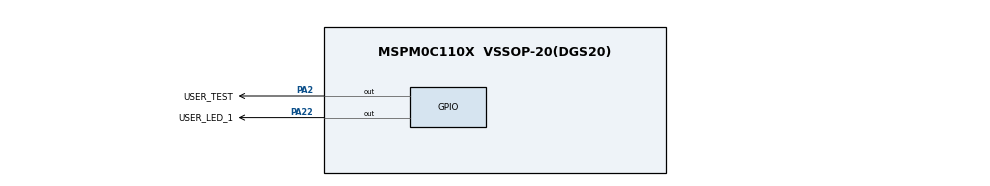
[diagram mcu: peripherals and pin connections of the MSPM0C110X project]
/**
 * @cliArgs --device "MSPM0C110X" --part "Default" --package "VSSOP-20(DGS20)" --product "mspm0_sdk@2.04.00.06"
 * @versions {"tool":"1.22.0+3893"}
 */

/**
 * Import the modules used in this configuration.
 */
const GPIO          = scripting.addModule("/ti/driverlib/GPIO", {}, false);
const GPIO1         = GPIO.addInstance();
const SYSCTL        = scripting.addModule("/ti/driverlib/SYSCTL");
const ProjectConfig = scripting.addModule("/ti/project_config/ProjectConfig");

/**
 * Write custom configuration values to the imported modules.
 */
GPIO1.$name                         = "GPIO_LEDS";
GPIO1.associatedPins.create(2);
GPIO1.associatedPins[0].$name       = "USER_LED_1";
GPIO1.associatedPins[0].pin.$assign = "PA22";
GPIO1.associatedPins[1].$name       = "USER_TEST";
GPIO1.associatedPins[1].pin.$assign = "PA2";

const Board = scripting.addModule("/ti/driverlib/Board", {}, false);

SYSCTL.clockTreeEn = true;

ProjectConfig.genLinker  = false;
ProjectConfig.genStartup = false;

/**
 * Pinmux solution for unlocked pins/peripherals. This ensures that minor changes to the automatic solver in a future
 * version of the tool will not impact the pinmux you originally saw.  These lines can be completely deleted in order to
 * re-solve from scratch.
 */
Board.peripheral.$suggestSolution          = "DEBUGSS";
Board.peripheral.swclkPin.$suggestSolution = "PA20";
Board.peripheral.swdioPin.$suggestSolution = "PA19";
